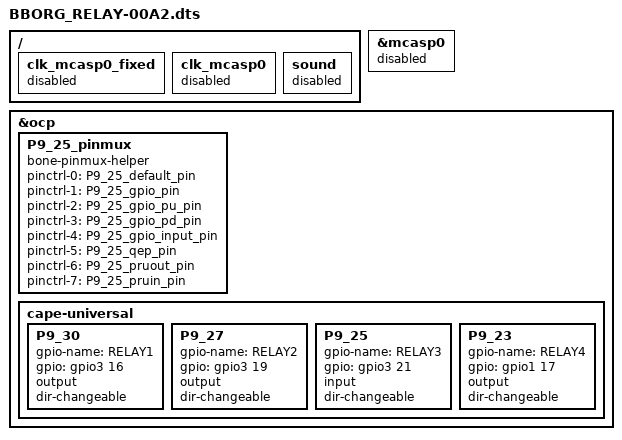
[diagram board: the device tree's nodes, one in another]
/*
 * Copyright (C) 2018 Texas Instruments, Jason Kridner <jdk@ti.com>
 *
 * This program is free software; you can redistribute it and/or modify
 * it under the terms of the GNU General Public License version 2 as
 * published by the Free Software Foundation.
 *
 * See https://github.com/beagleboard/capes
 */

/dts-v1/;
/plugin/;

#include <dt-bindings/gpio/gpio.h>
#include <dt-bindings/pinctrl/am33xx.h>
#include <dt-bindings/interrupt-controller/irq.h>

/ {
	/*
	 * Disable HDMI audio to free up P9_25
	 */
	fragment@0 {
		target-path = "/";
		__overlay__ {
			clk_mcasp0_fixed {
				status = "disabled";
			};
			clk_mcasp0 {
				status = "disabled";
			};
			sound {
				status = "disabled";
			};
		};
	};

	fragment@1 {
		target = <&mcasp0>;
		__overlay__ {
			status = "disabled";
		};
	};

	/*
	 * Add P9_25 pinmux helper
	 */
	fragment@2 {
		target = <&ocp>;
		__overlay__ {

			/* P9_25 (ZCZ ball A14) audio */
			P9_25_pinmux {
				compatible = "bone-pinmux-helper";
				status = "okay";
				pinctrl-names = "default", "gpio", "gpio_pu", "gpio_pd", "gpio_input", "qep", "pruout", "pruin";
				pinctrl-0 = <&P9_25_default_pin>;
				pinctrl-1 = <&P9_25_gpio_pin>;
				pinctrl-2 = <&P9_25_gpio_pu_pin>;
				pinctrl-3 = <&P9_25_gpio_pd_pin>;
				pinctrl-4 = <&P9_25_gpio_input_pin>;
				pinctrl-5 = <&P9_25_qep_pin>;
				pinctrl-6 = <&P9_25_pruout_pin>;
				pinctrl-7 = <&P9_25_pruin_pin>;
			};
		};
	};

	/*
	 * Update exported gpio labels and states
	 */
	fragment@3 {
		target = <&ocp>;
		__overlay__ {
			cape-universal {
				P9_30 {
					gpio-name = "RELAY1";
					gpio = <&gpio3 16 0>;
					output;
					dir-changeable;
				};

				P9_27 {
					gpio-name = "RELAY2";
					gpio = <&gpio3 19 0>;
					output;
					dir-changeable;
				};

				P9_25 {
					gpio-name = "RELAY3";
					gpio = <&gpio3 21 0>;
					input;
					dir-changeable;
				};

				P9_23 {
					gpio-name = "RELAY4";
					gpio = <&gpio1 17 0>;
					output;
					dir-changeable;
				};
			};
		};
	};
};
